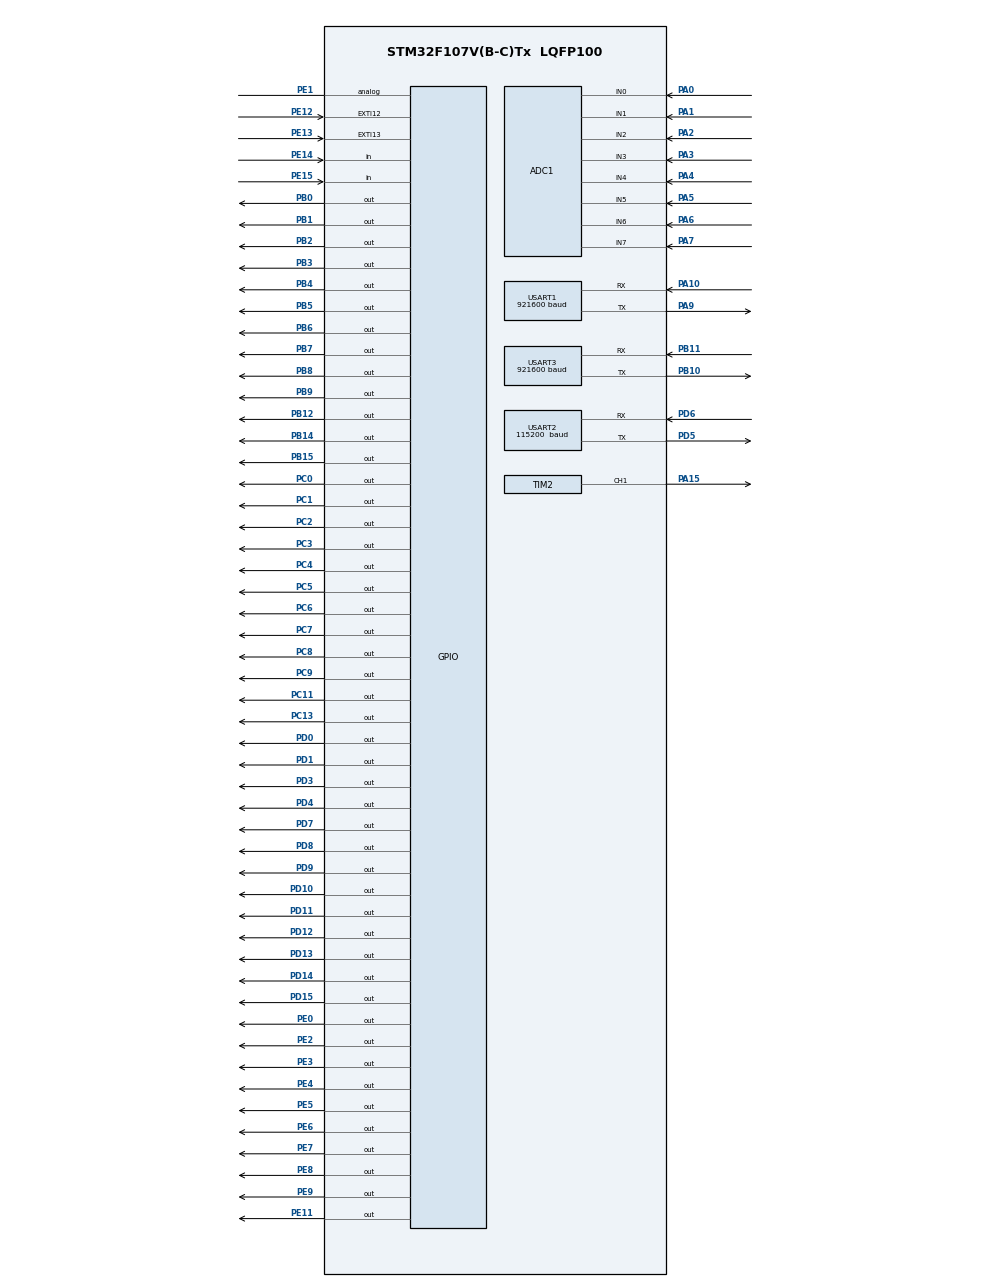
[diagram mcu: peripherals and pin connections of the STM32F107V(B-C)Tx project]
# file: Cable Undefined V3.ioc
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ADC1.Channel-1\#ChannelRegularConversion=ADC_CHANNEL_0
ADC1.Channel-2\#ChannelRegularConversion=ADC_CHANNEL_1
ADC1.Channel-3\#ChannelRegularConversion=ADC_CHANNEL_2
ADC1.Channel-4\#ChannelRegularConversion=ADC_CHANNEL_3
ADC1.Channel-5\#ChannelRegularConversion=ADC_CHANNEL_4
ADC1.Channel-6\#ChannelRegularConversion=ADC_CHANNEL_5
ADC1.Channel-7\#ChannelRegularConversion=ADC_CHANNEL_6
ADC1.Channel-8\#ChannelRegularConversion=ADC_CHANNEL_7
ADC1.ContinuousConvMode=ENABLE
ADC1.EnableAnalogWatchDog=false
ADC1.NbrOfConversion=8
ADC1.NbrOfConversionFlag=1
ADC1.Rank-1\#ChannelRegularConversion=1
ADC1.Rank-2\#ChannelRegularConversion=2
ADC1.Rank-3\#ChannelRegularConversion=3
ADC1.Rank-4\#ChannelRegularConversion=4
ADC1.Rank-5\#ChannelRegularConversion=5
ADC1.Rank-6\#ChannelRegularConversion=6
ADC1.Rank-7\#ChannelRegularConversion=7
ADC1.Rank-8\#ChannelRegularConversion=8
ADC1.SamplingTime-1\#ChannelRegularConversion=ADC_SAMPLETIME_13CYCLES_5
ADC1.SamplingTime-2\#ChannelRegularConversion=ADC_SAMPLETIME_13CYCLES_5
ADC1.SamplingTime-3\#ChannelRegularConversion=ADC_SAMPLETIME_13CYCLES_5
ADC1.SamplingTime-4\#ChannelRegularConversion=ADC_SAMPLETIME_13CYCLES_5
ADC1.SamplingTime-5\#ChannelRegularConversion=ADC_SAMPLETIME_13CYCLES_5
ADC1.SamplingTime-6\#ChannelRegularConversion=ADC_SAMPLETIME_13CYCLES_5
ADC1.SamplingTime-7\#ChannelRegularConversion=ADC_SAMPLETIME_13CYCLES_5
ADC1.SamplingTime-8\#ChannelRegularConversion=ADC_SAMPLETIME_13CYCLES_5
ADC1.master=1
Dma.ADC1.1.Direction=DMA_PERIPH_TO_MEMORY
Dma.ADC1.1.Instance=DMA1_Channel1
Dma.ADC1.1.MemDataAlignment=DMA_MDATAALIGN_HALFWORD
Dma.ADC1.1.MemInc=DMA_MINC_ENABLE
Dma.ADC1.1.Mode=DMA_CIRCULAR
Dma.ADC1.1.PeriphDataAlignment=DMA_PDATAALIGN_HALFWORD
Dma.ADC1.1.PeriphInc=DMA_PINC_DISABLE
Dma.ADC1.1.Priority=DMA_PRIORITY_HIGH
Dma.Request0=TIM2_CH1
Dma.Request1=ADC1
Dma.TIM2_CH1.0.Direction=DMA_MEMORY_TO_PERIPH
Dma.TIM2_CH1.0.Instance=DMA1_Channel5
Dma.TIM2_CH1.0.MemDataAlignment=DMA_MDATAALIGN_WORD
Dma.TIM2_CH1.0.MemInc=DMA_MINC_ENABLE
Dma.TIM2_CH1.0.Mode=DMA_NORMAL
Dma.TIM2_CH1.0.PeriphDataAlignment=DMA_PDATAALIGN_WORD
Dma.TIM2_CH1.0.PeriphInc=DMA_PINC_DISABLE
Dma.TIM2_CH1.0.Priority=DMA_PRIORITY_VERY_HIGH
Mcu.Family=STM32F1
Mcu.Name=STM32F107V(B-C)Tx
Mcu.Package=LQFP100
NVIC.DMA1_Channel1_IRQn=true\:0\:0\:false\:false\:true\:false\:true\:true
NVIC.DMA1_Channel5_IRQn=true\:0\:0\:false\:false\:true\:false\:true\:true
NVIC.EXTI15_10_IRQn=true\:0\:0\:true\:false\:true\:true\:true\:true
NVIC.PriorityGroup=NVIC_PRIORITYGROUP_4
NVIC.USART1_IRQn=true\:0\:0\:false\:false\:true\:true\:true\:true
NVIC.USART3_IRQn=true\:0\:0\:false\:false\:true\:true\:true\:true
OSC_IN.Mode=HSE-External-Oscillator
OSC_IN.Signal=RCC_OSC_IN
OSC_OUT.Mode=HSE-External-Oscillator
OSC_OUT.Signal=RCC_OSC_OUT
PA0-WKUP.Signal=ADCx_IN0
PA1.Signal=ADCx_IN1
PA10.Mode=Asynchronous
PA10.Signal=USART1_RX
PA13.Mode=Serial_Wire
PA13.Signal=SYS_JTMS-SWDIO
PA14.Mode=Serial_Wire
PA14.Signal=SYS_JTCK-SWCLK
PA15.Signal=S_TIM2_CH1_ETR
PA2.Signal=ADCx_IN2
PA3.Signal=ADCx_IN3
PA4.Signal=ADCx_IN4
PA5.Signal=ADCx_IN5
PA6.Signal=ADCx_IN6
PA7.Signal=ADCx_IN7
PA9.Mode=Asynchronous
PA9.Signal=USART1_TX
PB0.Signal=GPIO_Output
PB1.Signal=GPIO_Output
PB10.Mode=Asynchronous
PB10.Signal=USART3_TX
PB11.Mode=Asynchronous
PB11.Signal=USART3_RX
PB12.Signal=GPIO_Output
PB14.Signal=GPIO_Output
PB15.Signal=GPIO_Output
PB2.Signal=GPIO_Output
PB3.Signal=GPIO_Output
PB4.Signal=GPIO_Output
PB5.Signal=GPIO_Output
PB6.Signal=GPIO_Output
PB7.Signal=GPIO_Output
PB8.Signal=GPIO_Output
PB9.Signal=GPIO_Output
PC0.Signal=GPIO_Output
PC1.Signal=GPIO_Output
PC11.Signal=GPIO_Output
PC13-TAMPER-RTC.Signal=GPIO_Output
PC14-OSC32_IN.Mode=LSE-External-Oscillator
PC14-OSC32_IN.Signal=RCC_OSC32_IN
PC15-OSC32_OUT.Mode=LSE-External-Oscillator
PC15-OSC32_OUT.Signal=RCC_OSC32_OUT
PC2.Signal=GPIO_Output
PC3.Signal=GPIO_Output
PC4.Signal=GPIO_Output
PC5.Signal=GPIO_Output
PC6.Signal=GPIO_Output
PC7.Signal=GPIO_Output
PC8.Signal=GPIO_Output
PC9.Signal=GPIO_Output
PD0.Signal=GPIO_Output
PD1.Signal=GPIO_Output
PD10.Signal=GPIO_Output
PD11.Signal=GPIO_Output
PD12.Signal=GPIO_Output
PD13.Signal=GPIO_Output
PD14.Signal=GPIO_Output
PD15.Signal=GPIO_Output
PD3.Signal=GPIO_Output
PD4.Signal=GPIO_Output
PD5.Mode=Asynchronous
PD5.Signal=USART2_TX
PD6.Mode=Asynchronous
PD6.Signal=USART2_RX
PD7.Signal=GPIO_Output
PD8.Signal=GPIO_Output
PD9.Signal=GPIO_Output
PE0.Signal=GPIO_Output
PE1.Signal=GPIO_Analog
PE11.Signal=GPIO_Output
PE12.GPIO_ModeDefaultEXTI=GPIO_MODE_IT_FALLING
PE12.Signal=GPXTI12
PE13.GPIO_ModeDefaultEXTI=GPIO_MODE_IT_FALLING
PE13.Signal=GPXTI13
PE14.Signal=GPIO_Input
PE15.Signal=GPIO_Input
PE2.Signal=GPIO_Output
PE3.Signal=GPIO_Output
PE4.Signal=GPIO_Output
PE5.Signal=GPIO_Output
PE6.Signal=GPIO_Output
PE7.Signal=GPIO_Output
PE8.Signal=GPIO_Output
PE9.Signal=GPIO_Output
ProjectManager.HeapSize=0x200
ProjectManager.StackSize=0x400
ProjectManager.TargetToolchain=STM32CubeIDE
RCC.ADCPresc=RCC_ADCPCLK2_DIV6
RCC.AHBFreq_Value=72000000
RCC.APB1CLKDivider=RCC_HCLK_DIV2
RCC.APB1Freq_Value=36000000
RCC.APB1TimFreq_Value=72000000
RCC.APB2Freq_Value=72000000
RCC.APB2TimFreq_Value=72000000
RCC.HCLKFreq_Value=72000000
RCC.PLLMUL=RCC_PLL_MUL9
RCC.PLLSourceVirtual=RCC_PLLSOURCE_HSE
RCC.SYSCLKFreq_VALUE=72000000
RCC.SYSCLKSource=RCC_SYSCLKSOURCE_PLLCLK
RCC.USBFreq_Value=48000000
SH.ADCx_IN0.0=ADC1_IN0,IN0
SH.ADCx_IN1.0=ADC1_IN1,IN1
SH.ADCx_IN2.0=ADC1_IN2,IN2
SH.ADCx_IN3.0=ADC1_IN3,IN3
SH.ADCx_IN4.0=ADC1_IN4,IN4
SH.ADCx_IN5.0=ADC1_IN5,IN5
SH.ADCx_IN6.0=ADC1_IN6,IN6
SH.ADCx_IN7.0=ADC1_IN7,IN7
SH.S_TIM2_CH1_ETR.0=TIM2_CH1,PWM Generation1 CH1
TIM2.Channel-PWM\ Generation1\ CH1=TIM_CHANNEL_1
TIM2.Period=89
TIM6.Period=65535
TIM6.Prescaler=72
USART1.BaudRate=921600
USART1.VirtualMode=VM_ASYNC
USART2.BaudRate=115200 
USART2.VirtualMode=VM_ASYNC
USART3.BaudRate=921600
USART3.VirtualMode=VM_ASYNC
VP_TIM2_VS_ClockSourceINT.Mode=Internal
VP_TIM6_VS_ClockSourceINT.Mode=Enable_Timer
board=custom

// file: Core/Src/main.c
/* USER CODE BEGIN Header */
/**
  ******************************************************************************
  * @file           : main.c
  * @brief          : Main program body
  ******************************************************************************
  * @attention
  *
  * Copyright (c) 2025 STMicroelectronics.
  * All rights reserved.
  *
  * This software is licensed under terms that can be found in the LICENSE file
  * in the root directory of this software component.
  * If no LICENSE file comes with this software, it is provided AS-IS.
  *
  ******************************************************************************
  */
/* USER CODE END Header */
#include "main.h"

/* USER CODE BEGIN Includes */
#include "mux.h"
#include "serial.h"
#include "leds.h"
#include "signal_analyzer.h"
#include "fault.h"

#include <stdio.h>
#include <stdlib.h>

#include "stm32f1xx_ll_usart.h"
/* USER CODE END Includes */

void SystemClock_Config(void);
static void MX_GPIO_Init(void);
static void MX_DMA_Init(void);
static void MX_ADC1_Init(void);
static void MX_USART1_UART_Init(void);
static void MX_USART2_UART_Init(void);
static void MX_USART3_UART_Init(void);
static void MX_TIM6_Init(void);
static void MX_TIM2_Init(void);

/* USER CODE BEGIN 0 */

// Погледни чата с г-н Стефанов, _write e блокираща функция

int _write(int file, char *ptr, int len) {
    for (int i = 0; i < len; i++) {
        while (!LL_USART_IsActiveFlag_TXE(USART2));  // Wait until TX buffer is empty
        LL_USART_TransmitData8(USART2, ptr[i]);      // Send byte
    }

    while (!LL_USART_IsActiveFlag_TC(USART2));  // Wait for last transmission to complete
    return len;
}

/* USER CODE END 0 */

int main(void)
{

  /* MCU Configuration--------------------------------------------------------*/

  /* Reset of all peripherals, Initializes the Flash interface and the Systick. */
  LL_APB2_GRP1_EnableClock(LL_APB2_GRP1_PERIPH_AFIO);
  LL_APB1_GRP1_EnableClock(LL_APB1_GRP1_PERIPH_PWR);

  /* System interrupt init*/
  NVIC_SetPriorityGrouping(NVIC_PRIORITYGROUP_4);

  /* SysTick_IRQn interrupt configuration */
  NVIC_SetPriority(SysTick_IRQn, NVIC_EncodePriority(NVIC_GetPriorityGrouping(),15, 0));

  /** NOJTAG: JTAG-DP Disabled and SW-DP Enabled
  */
  LL_GPIO_AF_Remap_SWJ_NOJTAG();

  /* Configure the system clock */
  SystemClock_Config();

  /* Initialize all configured peripherals */
  MX_GPIO_Init();
  MX_DMA_Init();
  MX_ADC1_Init();
  MX_USART1_UART_Init();
  MX_USART2_UART_Init();
  MX_USART3_UART_Init();
  MX_TIM6_Init();
  MX_TIM2_Init();
  /* USER CODE BEGIN 2 */

  // Enable UART Interupts
  LL_USART_EnableIT_RXNE(USART1);
  LL_USART_EnableIT_RXNE(USART3);

  // Enable EXTI Fault GPIO Interrupts
  LL_EXTI_EnableIT_0_31(LL_EXTI_LINE_12);
  LL_EXTI_EnableIT_0_31(LL_EXTI_LINE_13);

  // Enable DMA Interrupt
  LL_DMA_EnableIT_TC(DMA1, LL_DMA_CHANNEL_5);

  LL_TIM_EnableCounter(TIM6);

  OscilloscopeInit();

  // Reset all Muxes
  LL_GPIO_SetOutputPin(RST_GPIO, RST_PIN);
  LL_mDelay(20);
  LL_GPIO_ResetOutputPin(RST_GPIO, RST_PIN);
  LL_mDelay(20);

  // Enable Protection
  LL_GPIO_SetOutputPin(PROTECTION_GPIO, PROTECTION_PIN);

  /* USER CODE END 2 */

  /* Infinite loop */
	  while (1)
	  {

    /* USER CODE BEGIN 3 */

		  sendADCData();
		  FAULT_CheckAndReport();  // Only sends UART if a fault was detected

	  }
  /* USER CODE END 3 */
}

void SystemClock_Config(void)
{
  LL_FLASH_SetLatency(LL_FLASH_LATENCY_2);
  while(LL_FLASH_GetLatency()!= LL_FLASH_LATENCY_2)
  {
  }
  LL_RCC_HSE_Enable();

   /* Wait till HSE is ready */
  while(LL_RCC_HSE_IsReady() != 1)
  {

  }
  LL_RCC_PLL_ConfigDomain_SYS(LL_RCC_PLLSOURCE_HSE_DIV_1, LL_RCC_PLL_MUL_9);
  LL_RCC_PLL_Enable();

   /* Wait till PLL is ready */
  while(LL_RCC_PLL_IsReady() != 1)
  {

  }
  LL_RCC_SetAHBPrescaler(LL_RCC_SYSCLK_DIV_1);
  LL_RCC_SetAPB1Prescaler(LL_RCC_APB1_DIV_2);
  LL_RCC_SetAPB2Prescaler(LL_RCC_APB2_DIV_1);
  LL_RCC_SetSysClkSource(LL_RCC_SYS_CLKSOURCE_PLL);

   /* Wait till System clock is ready */
  while(LL_RCC_GetSysClkSource() != LL_RCC_SYS_CLKSOURCE_STATUS_PLL)
  {

  }
  LL_Init1msTick(72000000);
  LL_SetSystemCoreClock(72000000);
  LL_RCC_SetADCClockSource(LL_RCC_ADC_CLKSRC_PCLK2_DIV_6);
}

static void MX_ADC1_Init(void)
{

  LL_ADC_InitTypeDef ADC_InitStruct = {0};
  LL_ADC_CommonInitTypeDef ADC_CommonInitStruct = {0};
  LL_ADC_REG_InitTypeDef ADC_REG_InitStruct = {0};

  LL_GPIO_InitTypeDef GPIO_InitStruct = {0};

  /* Peripheral clock enable */
  LL_APB2_GRP1_EnableClock(LL_APB2_GRP1_PERIPH_ADC1);

  LL_APB2_GRP1_EnableClock(LL_APB2_GRP1_PERIPH_GPIOA);
  /**ADC1 GPIO Configuration
  PA0-WKUP   ------> ADC1_IN0
  PA1   ------> ADC1_IN1
  PA2   ------> ADC1_IN2
  PA3   ------> ADC1_IN3
  PA4   ------> ADC1_IN4
  PA5   ------> ADC1_IN5
  PA6   ------> ADC1_IN6
  PA7   ------> ADC1_IN7
  */
  GPIO_InitStruct.Pin = LL_GPIO_PIN_0|LL_GPIO_PIN_1|LL_GPIO_PIN_2|LL_GPIO_PIN_3
                          |LL_GPIO_PIN_4|LL_GPIO_PIN_5|LL_GPIO_PIN_6|LL_GPIO_PIN_7;
  GPIO_InitStruct.Mode = LL_GPIO_MODE_ANALOG;
  LL_GPIO_Init(GPIOA, &GPIO_InitStruct);

  /* ADC1 DMA Init */

  /* ADC1 Init */
  LL_DMA_SetDataTransferDirection(DMA1, LL_DMA_CHANNEL_1, LL_DMA_DIRECTION_PERIPH_TO_MEMORY);

  LL_DMA_SetChannelPriorityLevel(DMA1, LL_DMA_CHANNEL_1, LL_DMA_PRIORITY_HIGH);

  LL_DMA_SetMode(DMA1, LL_DMA_CHANNEL_1, LL_DMA_MODE_CIRCULAR);

  LL_DMA_SetPeriphIncMode(DMA1, LL_DMA_CHANNEL_1, LL_DMA_PERIPH_NOINCREMENT);

  LL_DMA_SetMemoryIncMode(DMA1, LL_DMA_CHANNEL_1, LL_DMA_MEMORY_INCREMENT);

  LL_DMA_SetPeriphSize(DMA1, LL_DMA_CHANNEL_1, LL_DMA_PDATAALIGN_HALFWORD);

  LL_DMA_SetMemorySize(DMA1, LL_DMA_CHANNEL_1, LL_DMA_MDATAALIGN_HALFWORD);

  /** Common config
  */
  ADC_InitStruct.DataAlignment = LL_ADC_DATA_ALIGN_RIGHT;
  ADC_InitStruct.SequencersScanMode = LL_ADC_SEQ_SCAN_ENABLE;
  LL_ADC_Init(ADC1, &ADC_InitStruct);
  ADC_CommonInitStruct.Multimode = LL_ADC_MULTI_INDEPENDENT;
  LL_ADC_CommonInit(__LL_ADC_COMMON_INSTANCE(ADC1), &ADC_CommonInitStruct);
  ADC_REG_InitStruct.TriggerSource = LL_ADC_REG_TRIG_SOFTWARE;
  ADC_REG_InitStruct.SequencerLength = LL_ADC_REG_SEQ_SCAN_ENABLE_8RANKS;
  ADC_REG_InitStruct.SequencerDiscont = LL_ADC_REG_SEQ_DISCONT_DISABLE;
  ADC_REG_InitStruct.ContinuousMode = LL_ADC_REG_CONV_CONTINUOUS;
  ADC_REG_InitStruct.DMATransfer = LL_ADC_REG_DMA_TRANSFER_UNLIMITED;
  LL_ADC_REG_Init(ADC1, &ADC_REG_InitStruct);

  /** Configure Regular Channel
  */
  LL_ADC_REG_SetSequencerRanks(ADC1, LL_ADC_REG_RANK_1, LL_ADC_CHANNEL_0);
  LL_ADC_SetChannelSamplingTime(ADC1, LL_ADC_CHANNEL_0, LL_ADC_SAMPLINGTIME_13CYCLES_5);

  /** Configure Regular Channel
  */
  LL_ADC_REG_SetSequencerRanks(ADC1, LL_ADC_REG_RANK_2, LL_ADC_CHANNEL_1);
  LL_ADC_SetChannelSamplingTime(ADC1, LL_ADC_CHANNEL_1, LL_ADC_SAMPLINGTIME_13CYCLES_5);

  /** Configure Regular Channel
  */
  LL_ADC_REG_SetSequencerRanks(ADC1, LL_ADC_REG_RANK_3, LL_ADC_CHANNEL_2);
  LL_ADC_SetChannelSamplingTime(ADC1, LL_ADC_CHANNEL_2, LL_ADC_SAMPLINGTIME_13CYCLES_5);

  /** Configure Regular Channel
  */
  LL_ADC_REG_SetSequencerRanks(ADC1, LL_ADC_REG_RANK_4, LL_ADC_CHANNEL_3);
  LL_ADC_SetChannelSamplingTime(ADC1, LL_ADC_CHANNEL_3, LL_ADC_SAMPLINGTIME_13CYCLES_5);

  /** Configure Regular Channel
  */
  LL_ADC_REG_SetSequencerRanks(ADC1, LL_ADC_REG_RANK_5, LL_ADC_CHANNEL_4);
  LL_ADC_SetChannelSamplingTime(ADC1, LL_ADC_CHANNEL_4, LL_ADC_SAMPLINGTIME_13CYCLES_5);

  /** Configure Regular Channel
  */
  LL_ADC_REG_SetSequencerRanks(ADC1, LL_ADC_REG_RANK_6, LL_ADC_CHANNEL_5);
  LL_ADC_SetChannelSamplingTime(ADC1, LL_ADC_CHANNEL_5, LL_ADC_SAMPLINGTIME_13CYCLES_5);

  /** Configure Regular Channel
  */
  LL_ADC_REG_SetSequencerRanks(ADC1, LL_ADC_REG_RANK_7, LL_ADC_CHANNEL_6);
  LL_ADC_SetChannelSamplingTime(ADC1, LL_ADC_CHANNEL_6, LL_ADC_SAMPLINGTIME_13CYCLES_5);

  /** Configure Regular Channel
  */
  LL_ADC_REG_SetSequencerRanks(ADC1, LL_ADC_REG_RANK_8, LL_ADC_CHANNEL_7);
  LL_ADC_SetChannelSamplingTime(ADC1, LL_ADC_CHANNEL_7, LL_ADC_SAMPLINGTIME_13CYCLES_5);

}

static void MX_TIM2_Init(void)
{

  LL_TIM_InitTypeDef TIM_InitStruct = {0};
  LL_TIM_OC_InitTypeDef TIM_OC_InitStruct = {0};

  LL_GPIO_InitTypeDef GPIO_InitStruct = {0};

  /* Peripheral clock enable */
  LL_APB1_GRP1_EnableClock(LL_APB1_GRP1_PERIPH_TIM2);

  /* TIM2 DMA Init */

  /* TIM2_CH1 Init */
  LL_DMA_SetDataTransferDirection(DMA1, LL_DMA_CHANNEL_5, LL_DMA_DIRECTION_MEMORY_TO_PERIPH);

  LL_DMA_SetChannelPriorityLevel(DMA1, LL_DMA_CHANNEL_5, LL_DMA_PRIORITY_VERYHIGH);

  LL_DMA_SetMode(DMA1, LL_DMA_CHANNEL_5, LL_DMA_MODE_NORMAL);

  LL_DMA_SetPeriphIncMode(DMA1, LL_DMA_CHANNEL_5, LL_DMA_PERIPH_NOINCREMENT);

  LL_DMA_SetMemoryIncMode(DMA1, LL_DMA_CHANNEL_5, LL_DMA_MEMORY_INCREMENT);

  LL_DMA_SetPeriphSize(DMA1, LL_DMA_CHANNEL_5, LL_DMA_PDATAALIGN_WORD);

  LL_DMA_SetMemorySize(DMA1, LL_DMA_CHANNEL_5, LL_DMA_MDATAALIGN_WORD);

  TIM_InitStruct.Prescaler = 0;
  TIM_InitStruct.CounterMode = LL_TIM_COUNTERMODE_UP;
  TIM_InitStruct.Autoreload = 89;
  TIM_InitStruct.ClockDivision = LL_TIM_CLOCKDIVISION_DIV1;
  LL_TIM_Init(TIM2, &TIM_InitStruct);
  LL_TIM_DisableARRPreload(TIM2);
  LL_TIM_SetClockSource(TIM2, LL_TIM_CLOCKSOURCE_INTERNAL);
  LL_TIM_OC_EnablePreload(TIM2, LL_TIM_CHANNEL_CH1);
  TIM_OC_InitStruct.OCMode = LL_TIM_OCMODE_PWM1;
  TIM_OC_InitStruct.OCState = LL_TIM_OCSTATE_DISABLE;
  TIM_OC_InitStruct.OCNState = LL_TIM_OCSTATE_DISABLE;
  TIM_OC_InitStruct.CompareValue = 0;
  TIM_OC_InitStruct.OCPolarity = LL_TIM_OCPOLARITY_HIGH;
  LL_TIM_OC_Init(TIM2, LL_TIM_CHANNEL_CH1, &TIM_OC_InitStruct);
  LL_TIM_OC_DisableFast(TIM2, LL_TIM_CHANNEL_CH1);
  LL_TIM_SetTriggerOutput(TIM2, LL_TIM_TRGO_RESET);
  LL_TIM_DisableMasterSlaveMode(TIM2);
  LL_APB2_GRP1_EnableClock(LL_APB2_GRP1_PERIPH_GPIOA);
  /**TIM2 GPIO Configuration
  PA15   ------> TIM2_CH1
  */
  GPIO_InitStruct.Pin = LL_GPIO_PIN_15;
  GPIO_InitStruct.Mode = LL_GPIO_MODE_ALTERNATE;
  GPIO_InitStruct.Speed = LL_GPIO_SPEED_FREQ_LOW;
  GPIO_InitStruct.OutputType = LL_GPIO_OUTPUT_PUSHPULL;
  LL_GPIO_Init(GPIOA, &GPIO_InitStruct);

  LL_GPIO_AF_RemapPartial1_TIM2();

}

static void MX_TIM6_Init(void)
{

  LL_TIM_InitTypeDef TIM_InitStruct = {0};

  /* Peripheral clock enable */
  LL_APB1_GRP1_EnableClock(LL_APB1_GRP1_PERIPH_TIM6);

  TIM_InitStruct.Prescaler = 72;
  TIM_InitStruct.CounterMode = LL_TIM_COUNTERMODE_UP;
  TIM_InitStruct.Autoreload = 65535;
  LL_TIM_Init(TIM6, &TIM_InitStruct);
  LL_TIM_DisableARRPreload(TIM6);
  LL_TIM_SetTriggerOutput(TIM6, LL_TIM_TRGO_RESET);
  LL_TIM_DisableMasterSlaveMode(TIM6);

}

static void MX_USART1_UART_Init(void)
{

  LL_USART_InitTypeDef USART_InitStruct = {0};

  LL_GPIO_InitTypeDef GPIO_InitStruct = {0};

  /* Peripheral clock enable */
  LL_APB2_GRP1_EnableClock(LL_APB2_GRP1_PERIPH_USART1);

  LL_APB2_GRP1_EnableClock(LL_APB2_GRP1_PERIPH_GPIOA);
  /**USART1 GPIO Configuration
  PA9   ------> USART1_TX
  PA10   ------> USART1_RX
  */
  GPIO_InitStruct.Pin = LL_GPIO_PIN_9;
  GPIO_InitStruct.Mode = LL_GPIO_MODE_ALTERNATE;
  GPIO_InitStruct.Speed = LL_GPIO_SPEED_FREQ_HIGH;
  GPIO_InitStruct.OutputType = LL_GPIO_OUTPUT_PUSHPULL;
  LL_GPIO_Init(GPIOA, &GPIO_InitStruct);

  GPIO_InitStruct.Pin = LL_GPIO_PIN_10;
  GPIO_InitStruct.Mode = LL_GPIO_MODE_FLOATING;
  LL_GPIO_Init(GPIOA, &GPIO_InitStruct);

  /* USART1 interrupt Init */
  NVIC_SetPriority(USART1_IRQn, NVIC_EncodePriority(NVIC_GetPriorityGrouping(),0, 0));
  NVIC_EnableIRQ(USART1_IRQn);

  USART_InitStruct.BaudRate = 921600;
  USART_InitStruct.DataWidth = LL_USART_DATAWIDTH_8B;
  USART_InitStruct.StopBits = LL_USART_STOPBITS_1;
  USART_InitStruct.Parity = LL_USART_PARITY_NONE;
  USART_InitStruct.TransferDirection = LL_USART_DIRECTION_TX_RX;
  USART_InitStruct.HardwareFlowControl = LL_USART_HWCONTROL_NONE;
  USART_InitStruct.OverSampling = LL_USART_OVERSAMPLING_16;
  LL_USART_Init(USART1, &USART_InitStruct);
  LL_USART_ConfigAsyncMode(USART1);
  LL_USART_Enable(USART1);

}

static void MX_USART2_UART_Init(void)
{

  LL_USART_InitTypeDef USART_InitStruct = {0};

  LL_GPIO_InitTypeDef GPIO_InitStruct = {0};

  /* Peripheral clock enable */
  LL_APB1_GRP1_EnableClock(LL_APB1_GRP1_PERIPH_USART2);

  LL_APB2_GRP1_EnableClock(LL_APB2_GRP1_PERIPH_GPIOD);
  /**USART2 GPIO Configuration
  PD5   ------> USART2_TX
  PD6   ------> USART2_RX
  */
  GPIO_InitStruct.Pin = LL_GPIO_PIN_5;
  GPIO_InitStruct.Mode = LL_GPIO_MODE_ALTERNATE;
  GPIO_InitStruct.Speed = LL_GPIO_SPEED_FREQ_HIGH;
  GPIO_InitStruct.OutputType = LL_GPIO_OUTPUT_PUSHPULL;
  LL_GPIO_Init(GPIOD, &GPIO_InitStruct);

  GPIO_InitStruct.Pin = LL_GPIO_PIN_6;
  GPIO_InitStruct.Mode = LL_GPIO_MODE_FLOATING;
  LL_GPIO_Init(GPIOD, &GPIO_InitStruct);

  LL_GPIO_AF_EnableRemap_USART2();

  USART_InitStruct.BaudRate = 115200 ;
  USART_InitStruct.DataWidth = LL_USART_DATAWIDTH_8B;
  USART_InitStruct.StopBits = LL_USART_STOPBITS_1;
  USART_InitStruct.Parity = LL_USART_PARITY_NONE;
  USART_InitStruct.TransferDirection = LL_USART_DIRECTION_TX_RX;
  USART_InitStruct.HardwareFlowControl = LL_USART_HWCONTROL_NONE;
  USART_InitStruct.OverSampling = LL_USART_OVERSAMPLING_16;
  LL_USART_Init(USART2, &USART_InitStruct);
  LL_USART_ConfigAsyncMode(USART2);
  LL_USART_Enable(USART2);

}

static void MX_USART3_UART_Init(void)
{

  LL_USART_InitTypeDef USART_InitStruct = {0};

  LL_GPIO_InitTypeDef GPIO_InitStruct = {0};

  /* Peripheral clock enable */
  LL_APB1_GRP1_EnableClock(LL_APB1_GRP1_PERIPH_USART3);

  LL_APB2_GRP1_EnableClock(LL_APB2_GRP1_PERIPH_GPIOB);
  /**USART3 GPIO Configuration
  PB10   ------> USART3_TX
  PB11   ------> USART3_RX
  */
  GPIO_InitStruct.Pin = LL_GPIO_PIN_10;
  GPIO_InitStruct.Mode = LL_GPIO_MODE_ALTERNATE;
  GPIO_InitStruct.Speed = LL_GPIO_SPEED_FREQ_HIGH;
  GPIO_InitStruct.OutputType = LL_GPIO_OUTPUT_PUSHPULL;
  LL_GPIO_Init(GPIOB, &GPIO_InitStruct);

  GPIO_InitStruct.Pin = LL_GPIO_PIN_11;
  GPIO_InitStruct.Mode = LL_GPIO_MODE_FLOATING;
  LL_GPIO_Init(GPIOB, &GPIO_InitStruct);

  /* USART3 interrupt Init */
  NVIC_SetPriority(USART3_IRQn, NVIC_EncodePriority(NVIC_GetPriorityGrouping(),0, 0));
  NVIC_EnableIRQ(USART3_IRQn);

  USART_InitStruct.BaudRate = 921600;
  USART_InitStruct.DataWidth = LL_USART_DATAWIDTH_8B;
  USART_InitStruct.StopBits = LL_USART_STOPBITS_1;
  USART_InitStruct.Parity = LL_USART_PARITY_NONE;
  USART_InitStruct.TransferDirection = LL_USART_DIRECTION_TX_RX;
  USART_InitStruct.HardwareFlowControl = LL_USART_HWCONTROL_NONE;
  USART_InitStruct.OverSampling = LL_USART_OVERSAMPLING_16;
  LL_USART_Init(USART3, &USART_InitStruct);
  LL_USART_ConfigAsyncMode(USART3);
  LL_USART_Enable(USART3);

}

static void MX_DMA_Init(void)
{

  /* Init with LL driver */
  /* DMA controller clock enable */
  LL_AHB1_GRP1_EnableClock(LL_AHB1_GRP1_PERIPH_DMA1);

  /* DMA interrupt init */
  /* DMA1_Channel1_IRQn interrupt configuration */
  NVIC_SetPriority(DMA1_Channel1_IRQn, NVIC_EncodePriority(NVIC_GetPriorityGrouping(),0, 0));
  NVIC_EnableIRQ(DMA1_Channel1_IRQn);
  /* DMA1_Channel5_IRQn interrupt configuration */
  NVIC_SetPriority(DMA1_Channel5_IRQn, NVIC_EncodePriority(NVIC_GetPriorityGrouping(),0, 0));
  NVIC_EnableIRQ(DMA1_Channel5_IRQn);

}

static void MX_GPIO_Init(void)
{
  LL_EXTI_InitTypeDef EXTI_InitStruct = {0};
  LL_GPIO_InitTypeDef GPIO_InitStruct = {0};

  /* GPIO Ports Clock Enable */
  LL_APB2_GRP1_EnableClock(LL_APB2_GRP1_PERIPH_GPIOE);
  LL_APB2_GRP1_EnableClock(LL_APB2_GRP1_PERIPH_GPIOC);
  LL_APB2_GRP1_EnableClock(LL_APB2_GRP1_PERIPH_GPIOA);
  LL_APB2_GRP1_EnableClock(LL_APB2_GRP1_PERIPH_GPIOB);
  LL_APB2_GRP1_EnableClock(LL_APB2_GRP1_PERIPH_GPIOD);

  /**/
  LL_GPIO_ResetOutputPin(GPIOE, LL_GPIO_PIN_2|LL_GPIO_PIN_3|LL_GPIO_PIN_4|LL_GPIO_PIN_5
                          |LL_GPIO_PIN_6|LL_GPIO_PIN_7|LL_GPIO_PIN_8|LL_GPIO_PIN_9
                          |LL_GPIO_PIN_11|LL_GPIO_PIN_0);

  /**/
  LL_GPIO_ResetOutputPin(GPIOC, LL_GPIO_PIN_13|LL_GPIO_PIN_0|LL_GPIO_PIN_1|LL_GPIO_PIN_2
                          |LL_GPIO_PIN_3|LL_GPIO_PIN_4|LL_GPIO_PIN_5|LL_GPIO_PIN_6
                          |LL_GPIO_PIN_7|LL_GPIO_PIN_8|LL_GPIO_PIN_9|LL_GPIO_PIN_11);

  /**/
  LL_GPIO_ResetOutputPin(GPIOB, LL_GPIO_PIN_0|LL_GPIO_PIN_1|LL_GPIO_PIN_2|LL_GPIO_PIN_12
                          |LL_GPIO_PIN_14|LL_GPIO_PIN_15|LL_GPIO_PIN_3|LL_GPIO_PIN_4
                          |LL_GPIO_PIN_5|LL_GPIO_PIN_6|LL_GPIO_PIN_7|LL_GPIO_PIN_8
                          |LL_GPIO_PIN_9);

  /**/
  LL_GPIO_ResetOutputPin(GPIOD, LL_GPIO_PIN_8|LL_GPIO_PIN_9|LL_GPIO_PIN_10|LL_GPIO_PIN_11
                          |LL_GPIO_PIN_12|LL_GPIO_PIN_13|LL_GPIO_PIN_14|LL_GPIO_PIN_15
                          |LL_GPIO_PIN_0|LL_GPIO_PIN_1|LL_GPIO_PIN_3|LL_GPIO_PIN_4
                          |LL_GPIO_PIN_7);

  /**/
  GPIO_InitStruct.Pin = LL_GPIO_PIN_2|LL_GPIO_PIN_3|LL_GPIO_PIN_4|LL_GPIO_PIN_5
                          |LL_GPIO_PIN_6|LL_GPIO_PIN_7|LL_GPIO_PIN_8|LL_GPIO_PIN_9
                          |LL_GPIO_PIN_11|LL_GPIO_PIN_0;
  GPIO_InitStruct.Mode = LL_GPIO_MODE_OUTPUT;
  GPIO_InitStruct.Speed = LL_GPIO_SPEED_FREQ_LOW;
  GPIO_InitStruct.OutputType = LL_GPIO_OUTPUT_PUSHPULL;
  LL_GPIO_Init(GPIOE, &GPIO_InitStruct);

  /**/
  GPIO_InitStruct.Pin = LL_GPIO_PIN_13|LL_GPIO_PIN_0|LL_GPIO_PIN_1|LL_GPIO_PIN_2
                          |LL_GPIO_PIN_3|LL_GPIO_PIN_4|LL_GPIO_PIN_5|LL_GPIO_PIN_6
                          |LL_GPIO_PIN_7|LL_GPIO_PIN_8|LL_GPIO_PIN_9|LL_GPIO_PIN_11;
  GPIO_InitStruct.Mode = LL_GPIO_MODE_OUTPUT;
  GPIO_InitStruct.Speed = LL_GPIO_SPEED_FREQ_LOW;
  GPIO_InitStruct.OutputType = LL_GPIO_OUTPUT_PUSHPULL;
  LL_GPIO_Init(GPIOC, &GPIO_InitStruct);

  /**/
  GPIO_InitStruct.Pin = LL_GPIO_PIN_0|LL_GPIO_PIN_1|LL_GPIO_PIN_2|LL_GPIO_PIN_12
                          |LL_GPIO_PIN_14|LL_GPIO_PIN_15|LL_GPIO_PIN_3|LL_GPIO_PIN_4
                          |LL_GPIO_PIN_5|LL_GPIO_PIN_6|LL_GPIO_PIN_7|LL_GPIO_PIN_8
                          |LL_GPIO_PIN_9;
  GPIO_InitStruct.Mode = LL_GPIO_MODE_OUTPUT;
  GPIO_InitStruct.Speed = LL_GPIO_SPEED_FREQ_LOW;
  GPIO_InitStruct.OutputType = LL_GPIO_OUTPUT_PUSHPULL;
  LL_GPIO_Init(GPIOB, &GPIO_InitStruct);

  /**/
  GPIO_InitStruct.Pin = LL_GPIO_PIN_14|LL_GPIO_PIN_15;
  GPIO_InitStruct.Mode = LL_GPIO_MODE_FLOATING;
  LL_GPIO_Init(GPIOE, &GPIO_InitStruct);

  /**/
  GPIO_InitStruct.Pin = LL_GPIO_PIN_8|LL_GPIO_PIN_9|LL_GPIO_PIN_10|LL_GPIO_PIN_11
                          |LL_GPIO_PIN_12|LL_GPIO_PIN_13|LL_GPIO_PIN_14|LL_GPIO_PIN_15
                          |LL_GPIO_PIN_0|LL_GPIO_PIN_1|LL_GPIO_PIN_3|LL_GPIO_PIN_4
                          |LL_GPIO_PIN_7;
  GPIO_InitStruct.Mode = LL_GPIO_MODE_OUTPUT;
  GPIO_InitStruct.Speed = LL_GPIO_SPEED_FREQ_LOW;
  GPIO_InitStruct.OutputType = LL_GPIO_OUTPUT_PUSHPULL;
  LL_GPIO_Init(GPIOD, &GPIO_InitStruct);

  /**/
  GPIO_InitStruct.Pin = LL_GPIO_PIN_1;
  GPIO_InitStruct.Mode = LL_GPIO_MODE_ANALOG;
  LL_GPIO_Init(GPIOE, &GPIO_InitStruct);

  /**/
  LL_GPIO_AF_SetEXTISource(LL_GPIO_AF_EXTI_PORTE, LL_GPIO_AF_EXTI_LINE12);

  /**/
  LL_GPIO_AF_SetEXTISource(LL_GPIO_AF_EXTI_PORTE, LL_GPIO_AF_EXTI_LINE13);

  /**/
  EXTI_InitStruct.Line_0_31 = LL_EXTI_LINE_12;
  EXTI_InitStruct.LineCommand = ENABLE;
  EXTI_InitStruct.Mode = LL_EXTI_MODE_IT;
  EXTI_InitStruct.Trigger = LL_EXTI_TRIGGER_FALLING;
  LL_EXTI_Init(&EXTI_InitStruct);

  /**/
  EXTI_InitStruct.Line_0_31 = LL_EXTI_LINE_13;
  EXTI_InitStruct.LineCommand = ENABLE;
  EXTI_InitStruct.Mode = LL_EXTI_MODE_IT;
  EXTI_InitStruct.Trigger = LL_EXTI_TRIGGER_FALLING;
  LL_EXTI_Init(&EXTI_InitStruct);

  /**/
  LL_GPIO_SetPinMode(GPIOE, LL_GPIO_PIN_12, LL_GPIO_MODE_FLOATING);

  /**/
  LL_GPIO_SetPinMode(GPIOE, LL_GPIO_PIN_13, LL_GPIO_MODE_FLOATING);

  /* EXTI interrupt init*/
  NVIC_SetPriority(EXTI15_10_IRQn, NVIC_EncodePriority(NVIC_GetPriorityGrouping(),0, 0));
  NVIC_EnableIRQ(EXTI15_10_IRQn);

}

void Error_Handler(void)
{
  __disable_irq();
  while (1)
  {
  }
}
